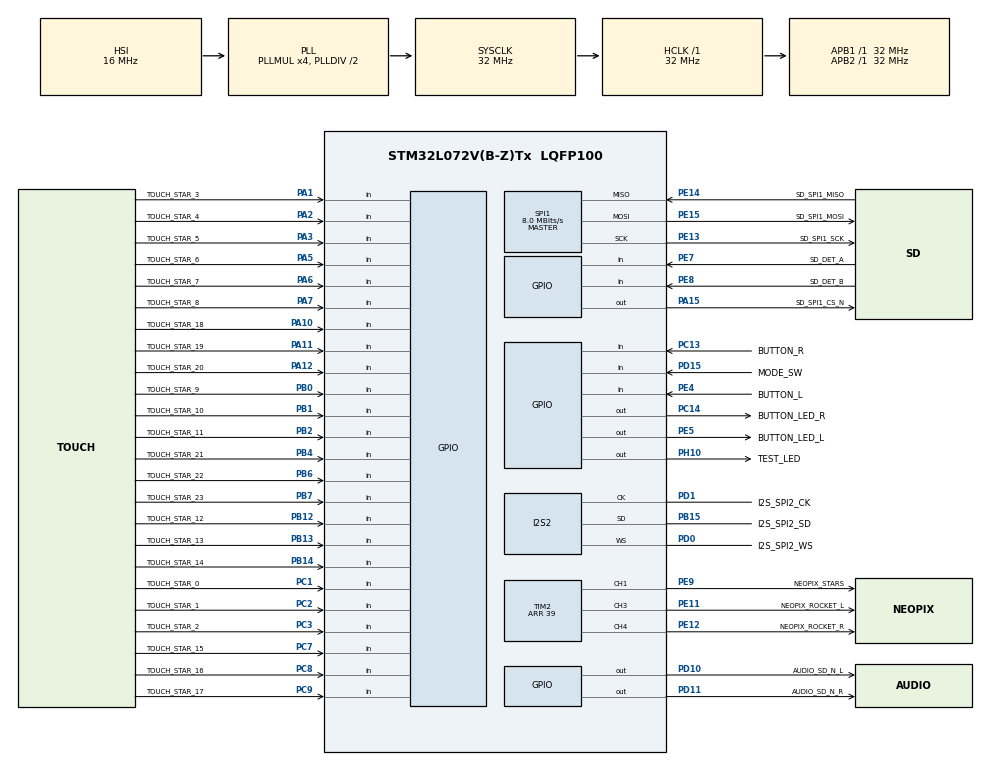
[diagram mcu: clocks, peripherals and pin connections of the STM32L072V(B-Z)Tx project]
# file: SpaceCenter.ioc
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Dma.Request0=TIM2_CH1
Dma.Request1=TIM2_CH3
Dma.Request2=TIM2_CH4
Dma.Request3=SPI1_RX
Dma.Request4=SPI2_TX
Dma.Request5=SPI1_TX
Dma.SPI1_RX.3.Direction=DMA_PERIPH_TO_MEMORY
Dma.SPI1_RX.3.Instance=DMA1_Channel2
Dma.SPI1_RX.3.MemDataAlignment=DMA_MDATAALIGN_BYTE
Dma.SPI1_RX.3.MemInc=DMA_MINC_ENABLE
Dma.SPI1_RX.3.Mode=DMA_NORMAL
Dma.SPI1_RX.3.PeriphDataAlignment=DMA_PDATAALIGN_BYTE
Dma.SPI1_RX.3.PeriphInc=DMA_PINC_DISABLE
Dma.SPI1_RX.3.Priority=DMA_PRIORITY_LOW
Dma.SPI1_TX.5.Direction=DMA_MEMORY_TO_PERIPH
Dma.SPI1_TX.5.Instance=DMA1_Channel3
Dma.SPI1_TX.5.MemDataAlignment=DMA_MDATAALIGN_BYTE
Dma.SPI1_TX.5.MemInc=DMA_MINC_ENABLE
Dma.SPI1_TX.5.Mode=DMA_NORMAL
Dma.SPI1_TX.5.PeriphDataAlignment=DMA_PDATAALIGN_BYTE
Dma.SPI1_TX.5.PeriphInc=DMA_PINC_DISABLE
Dma.SPI1_TX.5.Priority=DMA_PRIORITY_LOW
Dma.SPI2_TX.4.Direction=DMA_MEMORY_TO_PERIPH
Dma.SPI2_TX.4.Instance=DMA1_Channel7
Dma.SPI2_TX.4.MemDataAlignment=DMA_MDATAALIGN_HALFWORD
Dma.SPI2_TX.4.MemInc=DMA_MINC_ENABLE
Dma.SPI2_TX.4.Mode=DMA_NORMAL
Dma.SPI2_TX.4.PeriphDataAlignment=DMA_PDATAALIGN_HALFWORD
Dma.SPI2_TX.4.PeriphInc=DMA_PINC_DISABLE
Dma.SPI2_TX.4.Priority=DMA_PRIORITY_LOW
Dma.TIM2_CH1.0.Direction=DMA_MEMORY_TO_PERIPH
Dma.TIM2_CH1.0.Instance=DMA1_Channel5
Dma.TIM2_CH1.0.MemDataAlignment=DMA_MDATAALIGN_BYTE
Dma.TIM2_CH1.0.MemInc=DMA_MINC_ENABLE
Dma.TIM2_CH1.0.Mode=DMA_NORMAL
Dma.TIM2_CH1.0.PeriphDataAlignment=DMA_PDATAALIGN_WORD
Dma.TIM2_CH1.0.PeriphInc=DMA_PINC_DISABLE
Dma.TIM2_CH1.0.Priority=DMA_PRIORITY_LOW
Dma.TIM2_CH3.1.Direction=DMA_MEMORY_TO_PERIPH
Dma.TIM2_CH3.1.Instance=DMA1_Channel1
Dma.TIM2_CH3.1.MemDataAlignment=DMA_MDATAALIGN_BYTE
Dma.TIM2_CH3.1.MemInc=DMA_MINC_ENABLE
Dma.TIM2_CH3.1.Mode=DMA_NORMAL
Dma.TIM2_CH3.1.PeriphDataAlignment=DMA_PDATAALIGN_WORD
Dma.TIM2_CH3.1.PeriphInc=DMA_PINC_DISABLE
Dma.TIM2_CH3.1.Priority=DMA_PRIORITY_LOW
Dma.TIM2_CH4.2.Direction=DMA_MEMORY_TO_PERIPH
Dma.TIM2_CH4.2.Instance=DMA1_Channel4
Dma.TIM2_CH4.2.MemDataAlignment=DMA_MDATAALIGN_BYTE
Dma.TIM2_CH4.2.MemInc=DMA_MINC_ENABLE
Dma.TIM2_CH4.2.Mode=DMA_NORMAL
Dma.TIM2_CH4.2.PeriphDataAlignment=DMA_PDATAALIGN_WORD
Dma.TIM2_CH4.2.PeriphInc=DMA_PINC_DISABLE
Dma.TIM2_CH4.2.Priority=DMA_PRIORITY_LOW
I2S2.AudioFreq=I2S_AUDIOFREQ_44K
I2S2.CPOL=I2S_CPOL_HIGH
I2S2.ErrorAudioFreq=-1.18 %
I2S2.Instance=SPI$Index
I2S2.RealAudioFreq=43.478 KHz
I2S2.VirtualMode=I2S_MODE_MASTER
Mcu.Family=STM32L0
Mcu.Name=STM32L072V(B-Z)Tx
Mcu.Package=LQFP100
NVIC.DMA1_Channel1_IRQn=true\:0\:0\:false\:false\:true\:false\:true\:true
NVIC.DMA1_Channel2_3_IRQn=true\:0\:0\:false\:false\:true\:false\:true\:true
NVIC.DMA1_Channel4_5_6_7_IRQn=true\:0\:0\:false\:false\:true\:false\:true\:true
PA1.GPIO_Label=TOUCH_STAR_3
PA1.Signal=GPIO_Input
PA10.GPIO_Label=TOUCH_STAR_18
PA10.Signal=GPIO_Input
PA11.GPIO_Label=TOUCH_STAR_19
PA11.Signal=GPIO_Input
PA12.GPIO_Label=TOUCH_STAR_20
PA12.Signal=GPIO_Input
PA13.Mode=Serial_Wire
PA13.Signal=SYS_SWDIO
PA14.Mode=Serial_Wire
PA14.Signal=SYS_SWCLK
PA15.GPIO_Label=SD_SPI1_CS_N
PA15.Signal=GPIO_Output
PA2.GPIO_Label=TOUCH_STAR_4
PA2.Signal=GPIO_Input
PA3.GPIO_Label=TOUCH_STAR_5
PA3.Signal=GPIO_Input
PA5.GPIO_Label=TOUCH_STAR_6
PA5.Signal=GPIO_Input
PA6.GPIO_Label=TOUCH_STAR_7
PA6.Signal=GPIO_Input
PA7.GPIO_Label=TOUCH_STAR_8
PA7.Signal=GPIO_Input
PB0.GPIO_Label=TOUCH_STAR_9
PB0.Signal=GPIO_Input
PB1.GPIO_Label=TOUCH_STAR_10
PB1.Signal=GPIO_Input
PB12.GPIO_Label=TOUCH_STAR_12
PB12.Signal=GPIO_Input
PB13.GPIO_Label=TOUCH_STAR_13
PB13.Signal=GPIO_Input
PB14.GPIO_Label=TOUCH_STAR_14
PB14.Signal=GPIO_Input
PB15.GPIO_Label=I2S_SPI2_SD
PB15.GPIO_Speed=GPIO_SPEED_FREQ_VERY_HIGH
PB15.Mode=Half_Duplex_Master
PB15.Signal=I2S2_SD
PB2.GPIO_Label=TOUCH_STAR_11
PB2.Signal=GPIO_Input
PB4.GPIO_Label=TOUCH_STAR_21
PB4.Signal=GPIO_Input
PB6.GPIO_Label=TOUCH_STAR_22
PB6.Signal=GPIO_Input
PB7.GPIO_Label=TOUCH_STAR_23
PB7.Signal=GPIO_Input
PC0.GPIO_Label=TOUCH_G7_1_SAMP
PC0.Signal=TSC_G7_IO1
PC1.GPIO_Label=TOUCH_STAR_0
PC1.Signal=GPIO_Input
PC13.GPIO_Label=BUTTON_R
PC13.Signal=GPIO_Input
PC14-OSC32_IN.GPIO_Label=BUTTON_LED_R
PC14-OSC32_IN.Signal=GPIO_Output
PC2.GPIO_Label=TOUCH_STAR_1
PC2.Signal=GPIO_Input
PC3.GPIO_Label=TOUCH_STAR_2
PC3.Signal=GPIO_Input
PC7.GPIO_Label=TOUCH_STAR_15
PC7.Signal=GPIO_Input
PC8.GPIO_Label=TOUCH_STAR_16
PC8.Signal=GPIO_Input
PC9.GPIO_Label=TOUCH_STAR_17
PC9.Signal=GPIO_Input
PD0.GPIO_Label=I2S_SPI2_WS
PD0.GPIO_Speed=GPIO_SPEED_FREQ_VERY_HIGH
PD0.Mode=Half_Duplex_Master
PD0.Signal=I2S2_WS
PD1.GPIO_Label=I2S_SPI2_CK
PD1.GPIO_Speed=GPIO_SPEED_FREQ_VERY_HIGH
PD1.Mode=Half_Duplex_Master
PD1.Signal=I2S2_CK
PD10.GPIO_Label=AUDIO_SD_N_L
PD10.Signal=GPIO_Output
PD11.GPIO_Label=AUDIO_SD_N_R
PD11.GPIO_ModeDefaultOutputPP=GPIO_MODE_OUTPUT_OD
PD11.Signal=GPIO_Output
PD15.GPIO_Label=MODE_SW
PD15.Signal=GPIO_Input
PE11.GPIO_Label=NEOPIX_ROCKET_L
PE11.Signal=S_TIM2_CH3
PE12.GPIO_Label=NEOPIX_ROCKET_R
PE12.Signal=S_TIM2_CH4
PE13.GPIO_Label=SD_SPI1_SCK
PE13.Mode=Full_Duplex_Master
PE13.Signal=SPI1_SCK
PE14.GPIO_Label=SD_SPI1_MISO
PE14.Mode=Full_Duplex_Master
PE14.Signal=SPI1_MISO
PE15.GPIO_Label=SD_SPI1_MOSI
PE15.Mode=Full_Duplex_Master
PE15.Signal=SPI1_MOSI
PE4.GPIO_Label=BUTTON_L
PE4.Signal=GPIO_Input
PE5.GPIO_Label=BUTTON_LED_L
PE5.Signal=GPIO_Output
PE7.GPIO_Label=SD_DET_A
PE7.Signal=GPIO_Input
PE8.GPIO_Label=SD_DET_B
PE8.Signal=GPIO_Input
PE9.GPIO_Label=NEOPIX_STARS
PE9.Signal=S_TIM2_CH1
PH10.GPIO_Label=TEST_LED
PH10.Signal=GPIO_Output
ProjectManager.HeapSize=0x200
ProjectManager.StackSize=0x400
ProjectManager.TargetToolchain=STM32CubeIDE
RCC.AHBFreq_Value=32000000
RCC.APB1Freq_Value=32000000
RCC.APB1TimFreq_Value=32000000
RCC.APB2Freq_Value=32000000
RCC.APB2TimFreq_Value=32000000
RCC.HCLKFreq_Value=32000000
RCC.HSE_VALUE=8000000
RCC.HSI16_VALUE=16000000
RCC.HSI48_VALUE=48000000
RCC.HSI_VALUE=16000000
RCC.LSE_VALUE=32768
RCC.MSI_VALUE=2097000
RCC.PLLMUL=RCC_PLLMUL_4
RCC.SYSCLKFreq_VALUE=32000000
RCC.SYSCLKSource=RCC_SYSCLKSOURCE_PLLCLK
RCC.VCOOutputFreq_Value=64000000
SH.S_TIM2_CH1.0=TIM2_CH1,PWM Generation1 CH1
SH.S_TIM2_CH3.0=TIM2_CH3,PWM Generation3 CH3
SH.S_TIM2_CH4.0=TIM2_CH4,PWM Generation4 CH4
SPI1.BaudRatePrescaler=SPI_BAUDRATEPRESCALER_4
SPI1.CalculateBaudRate=8.0 MBits/s
SPI1.Direction=SPI_DIRECTION_2LINES
SPI1.Mode=SPI_MODE_MASTER
SPI1.VirtualType=VM_MASTER
TIM2.Channel-PWM\ Generation1\ CH1=TIM_CHANNEL_1
TIM2.Channel-PWM\ Generation3\ CH3=TIM_CHANNEL_3
TIM2.Channel-PWM\ Generation4\ CH4=TIM_CHANNEL_4
TIM2.OCFastMode_PWM-PWM\ Generation1\ CH1=TIM_OCFAST_ENABLE
TIM2.OCFastMode_PWM-PWM\ Generation3\ CH3=TIM_OCFAST_ENABLE
TIM2.OCFastMode_PWM-PWM\ Generation4\ CH4=TIM_OCFAST_ENABLE
TIM2.Period=39
VP_RNG_VS_RNG.Mode=RNG_Activate
VP_TIM2_VS_ClockSourceINT.Mode=Internal
board=custom

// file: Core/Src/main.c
/* USER CODE BEGIN Header */
/**
  ******************************************************************************
  * @file           : main.c
  * @brief          : Main program body
  ******************************************************************************
  * @attention
  *
  * <h2><center>&copy; Copyright (c) 2020 STMicroelectronics.
  * All rights reserved.</center></h2>
  *
  * This software component is licensed by ST under BSD 3-Clause license,
  * the "License"; You may not use this file except in compliance with the
  * License. You may obtain a copy of the License at:
  *                        opensource.org/licenses/BSD-3-Clause
  *
  ******************************************************************************
  */
/* USER CODE END Header */
#include "main.h"
#include "touchsensing.h"

/* USER CODE BEGIN Includes */
#include "string.h"
#include "diskio.h"
#include "ff.h"
#include "wav_player.h"
/* USER CODE END Includes */

I2S_HandleTypeDef hi2s2;
DMA_HandleTypeDef hdma_spi2_tx;

SPI_HandleTypeDef hspi1;
DMA_HandleTypeDef hdma_spi1_rx;

TIM_HandleTypeDef htim2;
DMA_HandleTypeDef hdma_tim2_ch1;
DMA_HandleTypeDef hdma_tim2_ch3;
DMA_HandleTypeDef hdma_tim2_ch4;

TSC_HandleTypeDef htsc;

void SystemClock_Config(void);
static void MX_GPIO_Init(void);
static void MX_DMA_Init(void);
static void MX_I2S2_Init(void);
static void MX_SPI1_Init(void);
static void MX_TSC_Init(void);
static void MX_TIM2_Init(void);

int main(void)
{

  /* MCU Configuration--------------------------------------------------------*/

  /* Reset of all peripherals, Initializes the Flash interface and the Systick. */
  HAL_Init();

  /* Configure the system clock */
  SystemClock_Config();

  /* Initialize all configured peripherals */
  MX_GPIO_Init();
  MX_DMA_Init();
  MX_I2S2_Init();
  MX_SPI1_Init();
  MX_TSC_Init();
  MX_TOUCHSENSING_Init();
  MX_TIM2_Init();

  /* Infinite loop */
  while (1)
  {

  }
}

void SystemClock_Config(void)
{
  RCC_OscInitTypeDef RCC_OscInitStruct = {0};
  RCC_ClkInitTypeDef RCC_ClkInitStruct = {0};

  /** Configure the main internal regulator output voltage
  */
  __HAL_PWR_VOLTAGESCALING_CONFIG(PWR_REGULATOR_VOLTAGE_SCALE1);
  /** Initializes the RCC Oscillators according to the specified parameters
  * in the RCC_OscInitTypeDef structure.
  */
  RCC_OscInitStruct.OscillatorType = RCC_OSCILLATORTYPE_HSI;
  RCC_OscInitStruct.HSIState = RCC_HSI_ON;
  RCC_OscInitStruct.HSICalibrationValue = RCC_HSICALIBRATION_DEFAULT;
  RCC_OscInitStruct.PLL.PLLState = RCC_PLL_ON;
  RCC_OscInitStruct.PLL.PLLSource = RCC_PLLSOURCE_HSI;
  RCC_OscInitStruct.PLL.PLLMUL = RCC_PLLMUL_4;
  RCC_OscInitStruct.PLL.PLLDIV = RCC_PLLDIV_2;
  if (HAL_RCC_OscConfig(&RCC_OscInitStruct) != HAL_OK)
  {
    Error_Handler();
  }
  /** Initializes the CPU, AHB and APB buses clocks
  */
  RCC_ClkInitStruct.ClockType = RCC_CLOCKTYPE_HCLK|RCC_CLOCKTYPE_SYSCLK
                              |RCC_CLOCKTYPE_PCLK1|RCC_CLOCKTYPE_PCLK2;
  RCC_ClkInitStruct.SYSCLKSource = RCC_SYSCLKSOURCE_PLLCLK;
  RCC_ClkInitStruct.AHBCLKDivider = RCC_SYSCLK_DIV1;
  RCC_ClkInitStruct.APB1CLKDivider = RCC_HCLK_DIV1;
  RCC_ClkInitStruct.APB2CLKDivider = RCC_HCLK_DIV1;

  if (HAL_RCC_ClockConfig(&RCC_ClkInitStruct, FLASH_LATENCY_1) != HAL_OK)
  {
    Error_Handler();
  }
}

static void MX_I2S2_Init(void)
{

  hi2s2.Instance = SPI2;
  hi2s2.Init.Mode = I2S_MODE_MASTER_TX;
  hi2s2.Init.Standard = I2S_STANDARD_PHILIPS;
  hi2s2.Init.DataFormat = I2S_DATAFORMAT_16B;
  hi2s2.Init.MCLKOutput = I2S_MCLKOUTPUT_DISABLE;
  hi2s2.Init.AudioFreq = I2S_AUDIOFREQ_44K;
  hi2s2.Init.CPOL = I2S_CPOL_HIGH;
  if (HAL_I2S_Init(&hi2s2) != HAL_OK)
  {
    Error_Handler();
  }

}

static void MX_SPI1_Init(void)
{

  /* SPI1 parameter configuration*/
  hspi1.Instance = SPI1;
  hspi1.Init.Mode = SPI_MODE_MASTER;
  hspi1.Init.Direction = SPI_DIRECTION_2LINES;
  hspi1.Init.DataSize = SPI_DATASIZE_8BIT;
  hspi1.Init.CLKPolarity = SPI_POLARITY_LOW;
  hspi1.Init.CLKPhase = SPI_PHASE_1EDGE;
  hspi1.Init.NSS = SPI_NSS_HARD_OUTPUT;
  hspi1.Init.BaudRatePrescaler = SPI_BAUDRATEPRESCALER_2;
  hspi1.Init.FirstBit = SPI_FIRSTBIT_MSB;
  hspi1.Init.TIMode = SPI_TIMODE_DISABLE;
  hspi1.Init.CRCCalculation = SPI_CRCCALCULATION_DISABLE;
  hspi1.Init.CRCPolynomial = 7;
  if (HAL_SPI_Init(&hspi1) != HAL_OK)
  {
    Error_Handler();
  }

}

static void MX_TIM2_Init(void)
{

  TIM_ClockConfigTypeDef sClockSourceConfig = {0};
  TIM_MasterConfigTypeDef sMasterConfig = {0};
  TIM_OC_InitTypeDef sConfigOC = {0};

  htim2.Instance = TIM2;
  htim2.Init.Prescaler = 0;
  htim2.Init.CounterMode = TIM_COUNTERMODE_UP;
  htim2.Init.Period = 39;
  htim2.Init.ClockDivision = TIM_CLOCKDIVISION_DIV1;
  htim2.Init.AutoReloadPreload = TIM_AUTORELOAD_PRELOAD_DISABLE;
  if (HAL_TIM_Base_Init(&htim2) != HAL_OK)
  {
    Error_Handler();
  }
  sClockSourceConfig.ClockSource = TIM_CLOCKSOURCE_INTERNAL;
  if (HAL_TIM_ConfigClockSource(&htim2, &sClockSourceConfig) != HAL_OK)
  {
    Error_Handler();
  }
  if (HAL_TIM_PWM_Init(&htim2) != HAL_OK)
  {
    Error_Handler();
  }
  sMasterConfig.MasterOutputTrigger = TIM_TRGO_RESET;
  sMasterConfig.MasterSlaveMode = TIM_MASTERSLAVEMODE_DISABLE;
  if (HAL_TIMEx_MasterConfigSynchronization(&htim2, &sMasterConfig) != HAL_OK)
  {
    Error_Handler();
  }
  sConfigOC.OCMode = TIM_OCMODE_PWM1;
  sConfigOC.Pulse = 0;
  sConfigOC.OCPolarity = TIM_OCPOLARITY_HIGH;
  sConfigOC.OCFastMode = TIM_OCFAST_ENABLE;
  if (HAL_TIM_PWM_ConfigChannel(&htim2, &sConfigOC, TIM_CHANNEL_1) != HAL_OK)
  {
    Error_Handler();
  }
  if (HAL_TIM_PWM_ConfigChannel(&htim2, &sConfigOC, TIM_CHANNEL_3) != HAL_OK)
  {
    Error_Handler();
  }
  if (HAL_TIM_PWM_ConfigChannel(&htim2, &sConfigOC, TIM_CHANNEL_4) != HAL_OK)
  {
    Error_Handler();
  }
  HAL_TIM_MspPostInit(&htim2);

}

static void MX_TSC_Init(void)
{

  /** Configure the TSC peripheral
  */
  htsc.Instance = TSC;
  htsc.Init.CTPulseHighLength = TSC_CTPH_2CYCLES;
  htsc.Init.CTPulseLowLength = TSC_CTPL_2CYCLES;
  htsc.Init.SpreadSpectrum = DISABLE;
  htsc.Init.SpreadSpectrumDeviation = 1;
  htsc.Init.SpreadSpectrumPrescaler = TSC_SS_PRESC_DIV1;
  htsc.Init.PulseGeneratorPrescaler = TSC_PG_PRESC_DIV4;
  htsc.Init.MaxCountValue = TSC_MCV_8191;
  htsc.Init.IODefaultMode = TSC_IODEF_OUT_PP_LOW;
  htsc.Init.SynchroPinPolarity = TSC_SYNC_POLARITY_FALLING;
  htsc.Init.AcquisitionMode = TSC_ACQ_MODE_NORMAL;
  htsc.Init.MaxCountInterrupt = DISABLE;
  htsc.Init.ChannelIOs = TSC_GROUP1_IO2|TSC_GROUP1_IO3|TSC_GROUP1_IO4|TSC_GROUP2_IO2
                    |TSC_GROUP2_IO3|TSC_GROUP2_IO4|TSC_GROUP3_IO2|TSC_GROUP3_IO3
                    |TSC_GROUP3_IO4|TSC_GROUP4_IO2|TSC_GROUP4_IO3|TSC_GROUP4_IO4
                    |TSC_GROUP5_IO2|TSC_GROUP5_IO3|TSC_GROUP5_IO4|TSC_GROUP6_IO2
                    |TSC_GROUP6_IO3|TSC_GROUP6_IO4|TSC_GROUP7_IO2|TSC_GROUP7_IO3
                    |TSC_GROUP7_IO4|TSC_GROUP8_IO2|TSC_GROUP8_IO3|TSC_GROUP8_IO4;
  htsc.Init.ShieldIOs = 0;
  htsc.Init.SamplingIOs = TSC_GROUP1_IO1|TSC_GROUP2_IO1|TSC_GROUP3_IO1|TSC_GROUP4_IO1
                    |TSC_GROUP5_IO1|TSC_GROUP6_IO1|TSC_GROUP7_IO1|TSC_GROUP8_IO1;
  if (HAL_TSC_Init(&htsc) != HAL_OK)
  {
    Error_Handler();
  }

}

static void MX_DMA_Init(void)
{

  /* DMA controller clock enable */
  __HAL_RCC_DMA1_CLK_ENABLE();

  /* DMA interrupt init */
  /* DMA1_Channel1_IRQn interrupt configuration */
  HAL_NVIC_SetPriority(DMA1_Channel1_IRQn, 0, 0);
  HAL_NVIC_EnableIRQ(DMA1_Channel1_IRQn);
  /* DMA1_Channel2_3_IRQn interrupt configuration */
  HAL_NVIC_SetPriority(DMA1_Channel2_3_IRQn, 0, 0);
  HAL_NVIC_EnableIRQ(DMA1_Channel2_3_IRQn);
  /* DMA1_Channel4_5_6_7_IRQn interrupt configuration */
  HAL_NVIC_SetPriority(DMA1_Channel4_5_6_7_IRQn, 0, 0);
  HAL_NVIC_EnableIRQ(DMA1_Channel4_5_6_7_IRQn);

}

static void MX_GPIO_Init(void)
{
  GPIO_InitTypeDef GPIO_InitStruct = {0};

  /* GPIO Ports Clock Enable */
  __HAL_RCC_GPIOE_CLK_ENABLE();
  __HAL_RCC_GPIOC_CLK_ENABLE();
  __HAL_RCC_GPIOH_CLK_ENABLE();
  __HAL_RCC_GPIOA_CLK_ENABLE();
  __HAL_RCC_GPIOB_CLK_ENABLE();
  __HAL_RCC_GPIOD_CLK_ENABLE();

  /*Configure GPIO pin Output Level */
  HAL_GPIO_WritePin(BUTTON_LED_L_GPIO_Port, BUTTON_LED_L_Pin, GPIO_PIN_RESET);

  /*Configure GPIO pin Output Level */
  HAL_GPIO_WritePin(BUTTON_LED_R_GPIO_Port, BUTTON_LED_R_Pin, GPIO_PIN_RESET);

  /*Configure GPIO pin Output Level */
  HAL_GPIO_WritePin(TEST_LED_GPIO_Port, TEST_LED_Pin, GPIO_PIN_RESET);

  /*Configure GPIO pin Output Level */
  HAL_GPIO_WritePin(GPIOD, AUDIO_SD_N_L_Pin|AUDIO_SD_N_R_Pin, GPIO_PIN_RESET);

  /*Configure GPIO pins : BUTTON_L_Pin SD_DET_A_Pin SD_DET_B_Pin */
  GPIO_InitStruct.Pin = BUTTON_L_Pin|SD_DET_A_Pin|SD_DET_B_Pin;
  GPIO_InitStruct.Mode = GPIO_MODE_INPUT;
  GPIO_InitStruct.Pull = GPIO_NOPULL;
  HAL_GPIO_Init(GPIOE, &GPIO_InitStruct);

  /*Configure GPIO pin : BUTTON_LED_L_Pin */
  GPIO_InitStruct.Pin = BUTTON_LED_L_Pin;
  GPIO_InitStruct.Mode = GPIO_MODE_OUTPUT_PP;
  GPIO_InitStruct.Pull = GPIO_NOPULL;
  GPIO_InitStruct.Speed = GPIO_SPEED_FREQ_LOW;
  HAL_GPIO_Init(BUTTON_LED_L_GPIO_Port, &GPIO_InitStruct);

  /*Configure GPIO pin : BUTTON_R_Pin */
  GPIO_InitStruct.Pin = BUTTON_R_Pin;
  GPIO_InitStruct.Mode = GPIO_MODE_INPUT;
  GPIO_InitStruct.Pull = GPIO_NOPULL;
  HAL_GPIO_Init(BUTTON_R_GPIO_Port, &GPIO_InitStruct);

  /*Configure GPIO pin : BUTTON_LED_R_Pin */
  GPIO_InitStruct.Pin = BUTTON_LED_R_Pin;
  GPIO_InitStruct.Mode = GPIO_MODE_OUTPUT_PP;
  GPIO_InitStruct.Pull = GPIO_NOPULL;
  GPIO_InitStruct.Speed = GPIO_SPEED_FREQ_LOW;
  HAL_GPIO_Init(BUTTON_LED_R_GPIO_Port, &GPIO_InitStruct);

  /*Configure GPIO pin : TEST_LED_Pin */
  GPIO_InitStruct.Pin = TEST_LED_Pin;
  GPIO_InitStruct.Mode = GPIO_MODE_OUTPUT_PP;
  GPIO_InitStruct.Pull = GPIO_NOPULL;
  GPIO_InitStruct.Speed = GPIO_SPEED_FREQ_LOW;
  HAL_GPIO_Init(TEST_LED_GPIO_Port, &GPIO_InitStruct);

  /*Configure GPIO pin : AUDIO_SD_N_L_Pin */
  GPIO_InitStruct.Pin = AUDIO_SD_N_L_Pin;
  GPIO_InitStruct.Mode = GPIO_MODE_OUTPUT_PP;
  GPIO_InitStruct.Pull = GPIO_NOPULL;
  GPIO_InitStruct.Speed = GPIO_SPEED_FREQ_LOW;
  HAL_GPIO_Init(AUDIO_SD_N_L_GPIO_Port, &GPIO_InitStruct);

  /*Configure GPIO pin : AUDIO_SD_N_R_Pin */
  GPIO_InitStruct.Pin = AUDIO_SD_N_R_Pin;
  GPIO_InitStruct.Mode = GPIO_MODE_OUTPUT_OD;
  GPIO_InitStruct.Pull = GPIO_NOPULL;
  GPIO_InitStruct.Speed = GPIO_SPEED_FREQ_LOW;
  HAL_GPIO_Init(AUDIO_SD_N_R_GPIO_Port, &GPIO_InitStruct);

  /*Configure GPIO pin : MODE_SW_Pin */
  GPIO_InitStruct.Pin = MODE_SW_Pin;
  GPIO_InitStruct.Mode = GPIO_MODE_INPUT;
  GPIO_InitStruct.Pull = GPIO_NOPULL;
  HAL_GPIO_Init(MODE_SW_GPIO_Port, &GPIO_InitStruct);

}

void Error_Handler(void)
{
}

/************************ (C) COPYRIGHT STMicroelectronics *****END OF FILE****/
